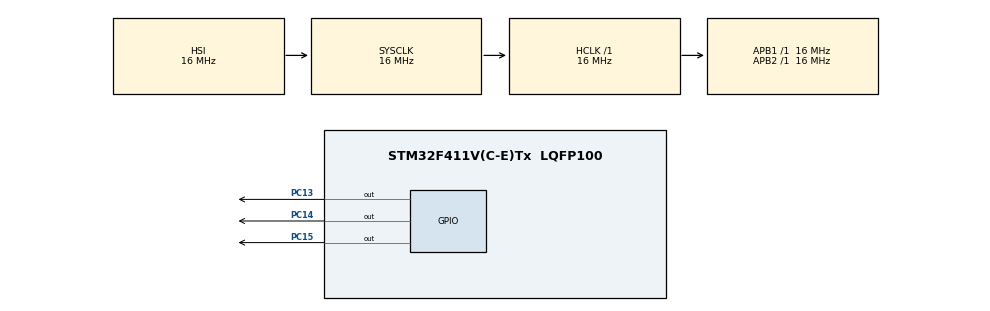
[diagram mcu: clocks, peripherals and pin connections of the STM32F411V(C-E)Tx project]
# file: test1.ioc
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Mcu.Family=STM32F4
Mcu.Name=STM32F411V(C-E)Tx
Mcu.Package=LQFP100
NVIC.PriorityGroup=NVIC_PRIORITYGROUP_4
PC13-ANTI_TAMP.Signal=GPIO_Output
PC14-OSC32_IN.Signal=GPIO_Output
PC15-OSC32_OUT.Signal=GPIO_Output
ProjectManager.HeapSize=0x200
ProjectManager.StackSize=0x400
ProjectManager.TargetToolchain=MDK-ARM V5
RCC.AHBFreq_Value=16000000
RCC.APB1Freq_Value=16000000
RCC.APB2Freq_Value=16000000
RCC.CortexFreq_Value=16000000
RCC.HSE_VALUE=25000000
RCC.HSI_VALUE=16000000
RCC.LSE_VALUE=32768
RCC.SYSCLKFreq_VALUE=16000000
RCC.VCOOutputFreq_Value=192000000
board=custom

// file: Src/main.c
/* USER CODE BEGIN Header */
/**
  ******************************************************************************
  * @file           : main.c
  * @brief          : Main program body
  ******************************************************************************
  * @attention
  *
  * <h2><center>&copy; Copyright (c) 2020 STMicroelectronics.
  * All rights reserved.</center></h2>
  *
  * This software component is licensed by ST under BSD 3-Clause license,
  * the "License"; You may not use this file except in compliance with the
  * License. You may obtain a copy of the License at:
  *                        opensource.org/licenses/BSD-3-Clause
  *
  ******************************************************************************
  */
/* USER CODE END Header */

#include "main.h"

/* USER CODE BEGIN PD */
#define u64 unsigned long long
#define u32 unsigned int
#define u16 unsigned short
#define u8  uint8_t
/* USER CODE END PD */

/* USER CODE BEGIN PM */
#define PC13_0  HAL_GPIO_WritePin(GPIOC, GPIO_PIN_13,GPIO_PIN_RESET)
#define PC13_1  HAL_GPIO_WritePin(GPIOC, GPIO_PIN_13,GPIO_PIN_SET)

#define PC14_0  HAL_GPIO_WritePin(GPIOC, GPIO_PIN_14,GPIO_PIN_RESET)
#define PC14_1  HAL_GPIO_WritePin(GPIOC, GPIO_PIN_14,GPIO_PIN_SET)

#define PC15_0  HAL_GPIO_WritePin(GPIOC, GPIO_PIN_15,GPIO_PIN_RESET)
#define PC15_1  HAL_GPIO_WritePin(GPIOC, GPIO_PIN_15,GPIO_PIN_SET)

#define LED1(a)     ((a==1)?PC13_1 : PC13_0)
#define LED2(a)     ((a==1)?PC14_1 : PC14_0)
#define LED3(a)     ((a==1)?PC15_1 : PC15_0)
/* USER CODE END PM */

/* USER CODE BEGIN PV */
uint32_t TIMER1;
u32 FLAG_T1;
u32 FLAG_T2;
/* USER CODE END PV */

void SystemClock_Config(void);
static void MX_GPIO_Init(void);

/* USER CODE BEGIN 0 */
void LED (void)
{

  if ((TIMER1<100)&&(FLAG_T1==0))
  {

    LED1(1);
    LED2(0);
    LED3(0);
    FLAG_T1=1;
  }

  if ((TIMER1>200)&&(FLAG_T2==0))
  {
    LED1(0);
    LED2(1);
    LED3(0);
    FLAG_T2=1;
  }

  if ((TIMER1>400))
  {
    LED1(0);
    LED2(0);
    LED3(1);
  }

  if (TIMER1>500)
  {
    TIMER1=0;
    FLAG_T1=0;
    FLAG_T2=0;
  }
}
/* USER CODE END 0 */

int main(void)
{

  /* MCU Configuration--------------------------------------------------------*/

  /* Reset of all peripherals, Initializes the Flash interface and the Systick. */
  HAL_Init();

  /* Configure the system clock */
  SystemClock_Config();

  /* Initialize all configured peripherals */
  MX_GPIO_Init();

  /* Infinite loop */
  while (1)
  {
  LED();
  }
}

void SystemClock_Config(void)
{
  RCC_OscInitTypeDef RCC_OscInitStruct = {0};
  RCC_ClkInitTypeDef RCC_ClkInitStruct = {0};

  /** Configure the main internal regulator output voltage
  */
  __HAL_RCC_PWR_CLK_ENABLE();
  __HAL_PWR_VOLTAGESCALING_CONFIG(PWR_REGULATOR_VOLTAGE_SCALE1);
  /** Initializes the CPU, AHB and APB busses clocks
  */
  RCC_OscInitStruct.OscillatorType = RCC_OSCILLATORTYPE_HSI;
  RCC_OscInitStruct.HSIState = RCC_HSI_ON;
  RCC_OscInitStruct.HSICalibrationValue = RCC_HSICALIBRATION_DEFAULT;
  RCC_OscInitStruct.PLL.PLLState = RCC_PLL_NONE;
  if (HAL_RCC_OscConfig(&RCC_OscInitStruct) != HAL_OK)
  {
    Error_Handler();
  }
  /** Initializes the CPU, AHB and APB busses clocks
  */
  RCC_ClkInitStruct.ClockType = RCC_CLOCKTYPE_HCLK|RCC_CLOCKTYPE_SYSCLK
                              |RCC_CLOCKTYPE_PCLK1|RCC_CLOCKTYPE_PCLK2;
  RCC_ClkInitStruct.SYSCLKSource = RCC_SYSCLKSOURCE_HSI;
  RCC_ClkInitStruct.AHBCLKDivider = RCC_SYSCLK_DIV1;
  RCC_ClkInitStruct.APB1CLKDivider = RCC_HCLK_DIV1;
  RCC_ClkInitStruct.APB2CLKDivider = RCC_HCLK_DIV1;

  if (HAL_RCC_ClockConfig(&RCC_ClkInitStruct, FLASH_LATENCY_0) != HAL_OK)
  {
    Error_Handler();
  }
}

static void MX_GPIO_Init(void)
{
  GPIO_InitTypeDef GPIO_InitStruct = {0};

  /* GPIO Ports Clock Enable */
  __HAL_RCC_GPIOC_CLK_ENABLE();

  /*Configure GPIO pin Output Level */
  HAL_GPIO_WritePin(GPIOC, GPIO_PIN_13|GPIO_PIN_14|GPIO_PIN_15, GPIO_PIN_RESET);

  /*Configure GPIO pins : PC13 PC14 PC15 */
  GPIO_InitStruct.Pin = GPIO_PIN_13|GPIO_PIN_14|GPIO_PIN_15;
  GPIO_InitStruct.Mode = GPIO_MODE_OUTPUT_PP;
  GPIO_InitStruct.Pull = GPIO_NOPULL;
  GPIO_InitStruct.Speed = GPIO_SPEED_FREQ_LOW;
  HAL_GPIO_Init(GPIOC, &GPIO_InitStruct);

}

void Error_Handler(void)
{
}

/************************ (C) COPYRIGHT STMicroelectronics *****END OF FILE****/
